# CY8C5888LTI_LP097 register map
File version: 0.1
CY8C58LP
Registers are 8-bit, read-write, no defined reset value unless marked. A register's access mark holds for its fields unless they carry their own. Offsets are from the block's base; lines under a group give offsets from that group; [hi:lo] are bit positions; {n}, {i} and the like mark numbered series; 'fields as' and 'values as' point back to an identical list; <NAME> marks a mode.

## Memory map
0x00000000 US_Timer
0x00000000 QD1_Timer
0x00000000 TB9051_QD1
0x00000000 TB9051_QD1_Cnt16
0x00000000 Timer_R
0x00000000 UART_RPi — UART
0x00000000 US_R
0x00000000 Stepper_EN
0x00000000 TB9051_QD2
0x00000000 TB9051_QD2_Cnt16
0x00000000 TB9051_EN
0x00000000 Timer_L
0x00000000 I2C_1
0x00000000 US_L

## US_Timer
Base 0x00000000
0x40006408 US_Timer_COUNTER 24-bit — UDB.A0 - Current Down Counter Value
0x40006428 US_Timer_PERIOD 24-bit — UDB.D0 - Assigned Period
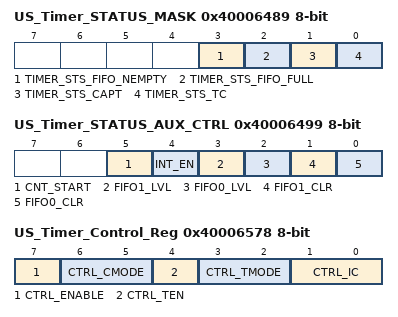
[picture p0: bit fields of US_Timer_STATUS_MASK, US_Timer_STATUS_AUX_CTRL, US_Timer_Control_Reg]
0x40006489 US_Timer_STATUS_MASK — UDB Status bits Interrupt Mask Enable Register
  [3] TIMER_STS_FIFO_NEMPTY ro — FIFO Empty status
  [2] TIMER_STS_FIFO_FULL ro — FIFO Full Status
  [1] TIMER_STS_CAPT ro — Enables the Interrupt on Capture
  [0] TIMER_STS_TC ro — Enables the Interrupt on TC
0x40006499 US_Timer_STATUS_AUX_CTRL — UDB Auxilliary Control Register
  [5] CNT_START — FIFO0 clear
    0=E_CNT_START0 (Disable counter); 1=E_CNT_START1 (Enable counter)
  [4] INT_EN
    0=E_INT_EN0 (Interrupt disabled); 1=E_INT_EN1 (Interrupt enabled)
  [3] FIFO1_LVL — FIFO level
    0=E_FIFO_LVL_0 (FIFO LVL: input mode: FIFO not full; output mode: FIFO not empty); 1=E_FIFO_LVL_1 (FIFO LVL: input mode: FIFO at least 1/2 empty; output mode: FIFO at least 1/2 full)
  [2] FIFO0_LVL — FIFO level
    values as FIFO1_LVL
  [1] FIFO1_CLR — FIFO1 clear
    0=E_FIFO_CLR_0 (Normal FIFO operation); 1=E_FIFO_CLR_1 (Clear FIFO state)
  [0] FIFO0_CLR — FIFO0 clear
    values as FIFO1_CLR
0x40006578 US_Timer_Control_Reg — UDB Control Register - Assigned Control Register Value
  [7] CTRL_ENABLE — Enable the Timer
  [6:5] CTRL_CMODE — Capture Mode
  [4] CTRL_TEN — Trigger Enable Bit
  [3:2] CTRL_TMODE — Trigger Mode
  [1:0] CTRL_IC — Interrupt Count

## QD1_Timer
Base 0x00000000
0x40006404 QD1_Timer_COUNTER 24-bit — UDB.A0 - Current Down Counter Value
0x40006424 QD1_Timer_PERIOD 24-bit — UDB.D0 - Assigned Period
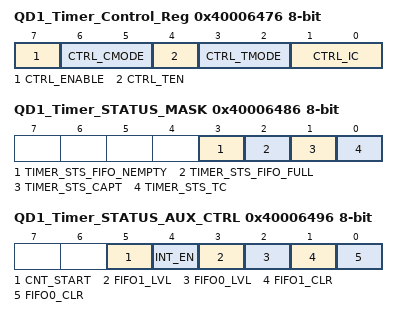
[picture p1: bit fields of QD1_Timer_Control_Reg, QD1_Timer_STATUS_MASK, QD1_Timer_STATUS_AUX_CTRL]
0x40006476 QD1_Timer_Control_Reg — UDB Control Register - Assigned Control Register Value
  [7] CTRL_ENABLE — Enable the Timer
  [6:5] CTRL_CMODE — Capture Mode
  [4] CTRL_TEN — Trigger Enable Bit
  [3:2] CTRL_TMODE — Trigger Mode
  [1:0] CTRL_IC — Interrupt Count
0x40006486 QD1_Timer_STATUS_MASK — UDB Status bits Interrupt Mask Enable Register
  [3] TIMER_STS_FIFO_NEMPTY ro — FIFO Empty status
  [2] TIMER_STS_FIFO_FULL ro — FIFO Full Status
  [1] TIMER_STS_CAPT ro — Enables the Interrupt on Capture
  [0] TIMER_STS_TC ro — Enables the Interrupt on TC
0x40006496 QD1_Timer_STATUS_AUX_CTRL — UDB Auxilliary Control Register
  [5] CNT_START — FIFO0 clear
    0=E_CNT_START0 (Disable counter); 1=E_CNT_START1 (Enable counter)
  [4] INT_EN
    0=E_INT_EN0 (Interrupt disabled); 1=E_INT_EN1 (Interrupt enabled)
  [3] FIFO1_LVL — FIFO level
    0=E_FIFO_LVL_0 (FIFO LVL: input mode: FIFO not full; output mode: FIFO not empty); 1=E_FIFO_LVL_1 (FIFO LVL: input mode: FIFO at least 1/2 empty; output mode: FIFO at least 1/2 full)
  [2] FIFO0_LVL — FIFO level
    values as FIFO1_LVL
  [1] FIFO1_CLR — FIFO1 clear
    0=E_FIFO_CLR_0 (Normal FIFO operation); 1=E_FIFO_CLR_1 (Clear FIFO state)
  [0] FIFO0_CLR — FIFO0 clear
    values as FIFO1_CLR

## TB9051_QD1
Base 0x00000000
0x4000640D TB9051_QD1_Cnt16_COUNTER 16-bit — Counter value
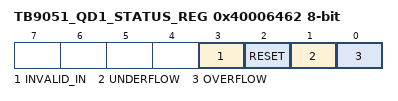
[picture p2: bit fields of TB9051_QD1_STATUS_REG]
0x40006462 TB9051_QD1_STATUS_REG — Quadrature Decoder Status Register
  [3] INVALID_IN ro — Invalid state transition on the A and B inputs
  [2] RESET ro — Counter Reset due index
  [1] UNDERFLOW ro — Counter underflow
  [0] OVERFLOW ro — Counter overflow

## TB9051_QD1_Cnt16
Base 0x00000000; alternate view of TB9051_QD1
0x4000640D TB9051_QD1_Cnt16_COUNTER 16-bit — UDB.A0 - Current Counter Value
0x4000642D TB9051_QD1_Cnt16_PERIOD 16-bit — UDB.D0 - Assigned Period
0x4000643D TB9051_QD1_Cnt16_COMPARE 16-bit — UDB.D1 - Assigned Compare Value
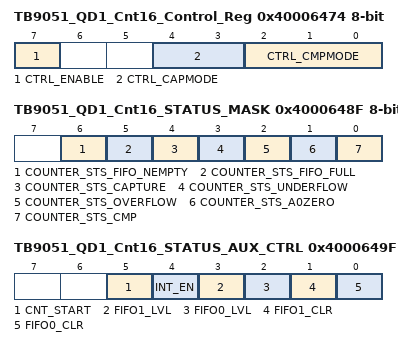
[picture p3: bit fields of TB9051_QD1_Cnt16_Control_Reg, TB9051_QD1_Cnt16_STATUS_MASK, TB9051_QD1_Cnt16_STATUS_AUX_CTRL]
0x40006474 TB9051_QD1_Cnt16_Control_Reg — UDB Control Register - Assigned Control Register Value
  [7] CTRL_ENABLE — Enable Counter
  [4:3] CTRL_CAPMODE — Capture mode
  [2:0] CTRL_CMPMODE — Compare mode
0x4000648F TB9051_QD1_Cnt16_STATUS_MASK — UDB Status bits Interrupt Mask Enable Register
  [6] COUNTER_STS_FIFO_NEMPTY — FIFO Not Empty Status
  [5] COUNTER_STS_FIFO_FULL — FIFO Full Status
  [4] COUNTER_STS_CAPTURE — Capture Status
  [3] COUNTER_STS_UNDERFLOW — Underflow status
  [2] COUNTER_STS_OVERFLOW — Overflow status
  [1] COUNTER_STS_A0ZERO — A0 Zero ouput status
  [0] COUNTER_STS_CMP — Compare output status
0x4000649F TB9051_QD1_Cnt16_STATUS_AUX_CTRL — UDB Auxilliary Control Register
  [5] CNT_START — FIFO0 clear
    0=E_CNT_START0 (Disable counter); 1=E_CNT_START1 (Enable counter)
  [4] INT_EN
    0=E_INT_EN0 (Interrupt disabled); 1=E_INT_EN1 (Interrupt enabled)
  [3] FIFO1_LVL — FIFO level
    0=E_FIFO_LVL_0 (FIFO LVL: input mode: FIFO not full; output mode: FIFO not empty); 1=E_FIFO_LVL_1 (FIFO LVL: input mode: FIFO at least 1/2 empty; output mode: FIFO at least 1/2 full)
  [2] FIFO0_LVL — FIFO level
    values as FIFO1_LVL
  [1] FIFO1_CLR — FIFO1 clear
    0=E_FIFO_CLR_0 (Normal FIFO operation); 1=E_FIFO_CLR_1 (Clear FIFO state)
  [0] FIFO0_CLR — FIFO0 clear
    values as FIFO1_CLR
